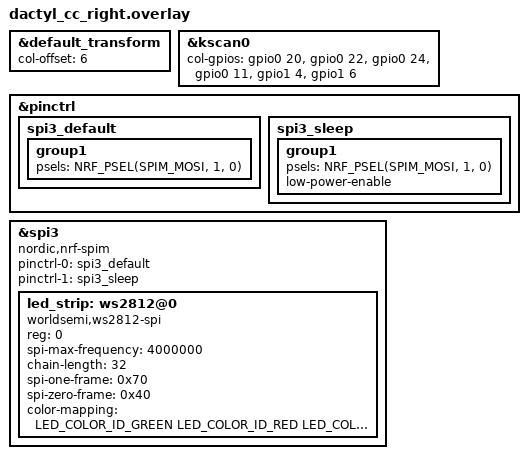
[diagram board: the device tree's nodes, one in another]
// dactyl_cc_right.overlay

#include "dactyl_cc.dtsi"
#include <dt-bindings/led/led.h>

&default_transform { // The matrix transform for this board is 6 columns over because the left half is 6 columns wide according to the matrix.
    col-offset = <6>;
};

&kscan0 {
    col-gpios
        = <&gpio0 20 GPIO_ACTIVE_HIGH> // col5 in the schematic
        , <&gpio0 22 GPIO_ACTIVE_HIGH> // col4 in the schematic
        , <&gpio0 24 GPIO_ACTIVE_HIGH> // col3 in the schematic
        , <&gpio0 11 GPIO_ACTIVE_HIGH> // col2 in the schematic
        , <&gpio1 4  GPIO_ACTIVE_HIGH> // col1 in the schematic
        , <&gpio1 6  GPIO_ACTIVE_HIGH> // col0 in the schematic
        ;
};


#include <dt-bindings/led/led.h>

&pinctrl {
    spi3_default: spi3_default {
        group1 {
            psels = <NRF_PSEL(SPIM_MOSI, 1, 0)>;
        };
    };

    spi3_sleep: spi3_sleep {
        group1 {
            psels = <NRF_PSEL(SPIM_MOSI, 1, 0)>;
            low-power-enable;
        };
    };
};

&spi3 {
  compatible = "nordic,nrf-spim";
  status = "okay";

  pinctrl-0 = <&spi3_default>;
  pinctrl-1 = <&spi3_sleep>;
  pinctrl-names = "default", "sleep";

  led_strip: ws2812@0 {
    compatible = "worldsemi,ws2812-spi";

    /* SPI */
    reg = <0>; /* ignored, but necessary for SPI bindings */
    spi-max-frequency = <4000000>;

    /* WS2812 */
    chain-length = <32>; /* number of LEDs */
    spi-one-frame = <0x70>;
    spi-zero-frame = <0x40>;
    color-mapping = <LED_COLOR_ID_GREEN
                          LED_COLOR_ID_RED
                          LED_COLOR_ID_BLUE>;
  };
};
